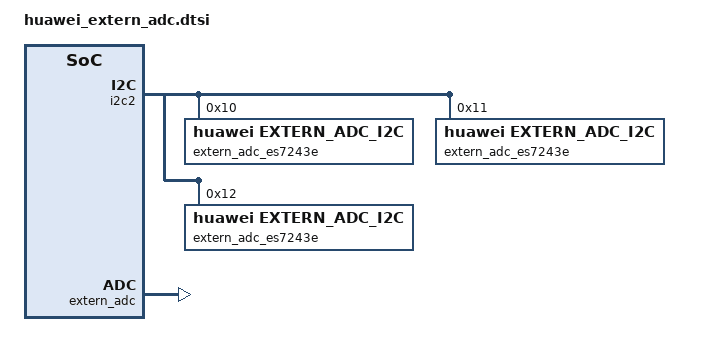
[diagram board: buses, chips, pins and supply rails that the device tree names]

&i2c2 {
	#address-cells = <1>;
	#size-cells = <0>;
	extern_adc_es7243e@10{
				compatible = "huawei,extern_adc_i2c";
				reg = <0x10>;
				chip_id = <2>;
				chip_model = "es7243e";
				status = "okay";

				/* reg_ctl node: a node contains five data <addr mask value delay ctl_type> */
				version_regs = <
					0xfd 0xff 0x7a 0 0
					0xfe 0xff 0x43 0 0
				>;

				init_regs = <
					0xf9 0xff 0x00 0 1
					0x02 0xff 0x80 0 1
					0x03 0xff 0x20 0 1
					0x0d 0xff 0xc0 0 1
					0x04 0xff 0x01 0 1
					0x05 0xff 0x00 0 1
					0x09 0xff 0xc5 0 1
					0x0a 0xff 0x81 0 1
					0x0b 0xff 0x00 0 1
					0x0c 0xff 0x13 0 1
					0x0e 0xff 0xbf 0 1
					0x0f 0xff 0x80 0 1
					0x14 0xff 0x04 0 1
					0x15 0xff 0x04 0 1
					0x16 0xff 0x00 0 1
					0x18 0xff 0x26 0 1
					0x17 0xff 0x02 0 1
					0x19 0xff 0x66 0 1
					0x1a 0xff 0x44 0 1
					0x1b 0xff 0x44 0 1
					0x1c 0xff 0x44 0 1
					0x1d 0xff 0x3c 0 1
					0x1e 0xff 0x0f 0 1
					0x1f 0xff 0x07 0 1
					0x20 0xff 0x10 0 1
					0x21 0xff 0x10 0 1
					0x00 0xff 0x80 0 1
					0x01 0xff 0x3a 0 1
					0x16 0xff 0x3f 0 1
					0x16 0xff 0x00 20 1
					0x16 0xff 0x03 20 1
					0x16 0xff 0x00 0 1
					0x14 0xff 0x0c 0 1
					0x15 0xff 0x0c 0 1
					0x20 0xff 0x1a 0 1
					0x21 0xff 0x1a 0 1
					0x0b 0xc0 0xc0 0 1
					0x04 0xff 0x02 0 1
					0x04 0xff 0x01 0 1
					0xf7 0xff 0x30 0 1
					0xf9 0xff 0x01 0 1
					0x16 0xff 0xff 0 1
					0x01 0xff 0x38 0 1
					0x20 0x10 0x00 0 1
					0x21 0x10 0x00 0 1
					0x00 0xff 0x00 0 1
					0x00 0xff 0x1e 0 1
					0x01 0xff 0x30 0 1
					0x01 0xff 0x00 0 1
				>;

				poweron_regs = <
					0x01 0xff 0x3a 0 1
					0x0b 0xc0 0xc0 0 1
					0x00 0xff 0x80 0 1
					0x14 0x1f 0x04 0 1
					0x15 0x1f 0x04 0 1
					0x16 0xff 0x00 0 1
					0x17 0xff 0x02 0 1
					0x14 0x1f 0x0c 40 1
					0x15 0x1f 0x0c 0 1
					0x20 0x10 0x10 0 1
					0x21 0x10 0x10 0 1
					0x0b 0xc0 0x00 40 1
				>;

				poweroff_regs = <
					0x0b 0xc0 0xc0 0 1
					0x04 0xff 0x02 20 1
					0x04 0xff 0x01 0 1
					0xf7 0xff 0x30 0 1
					0xf9 0xff 0x01 0 1
					0x16 0xff 0xff 0 1
					0x17 0xff 0x00 0 1
					0x01 0xff 0x38 0 1
					0x20 0x10 0x00 0 1
					0x21 0x10 0x00 0 1
					0x00 0xff 0x00 0 1
					0x00 0xff 0x1e 0 1
					0x01 0xff 0x30 0 1
					0x01 0xff 0x00 0 1
				>;

				/* pga_regs: a node contains five data <addr mask min_value delay max_value> */
				pga_volume_regs = <
					0x20 0x0f 0 0 14
					0x21 0x0f 0 0 14
				>;

				/* kctl_regs: always only has one elem, a node contains five data<addr mask min_value delay max_value> */
				tdm_mode_regs = <
					0x0c 0x0f 0 0 9
				>;

				data_sel_regs = <
					0x0d 0xc0 0 0 3
				>;

				mute_ctl_regs = <
					0x0b 0xc0 0 0 3
				>;

				/* dump reg ctl node: < addr reg_nums 0 0 ctl_type:5> */
				dump_regs = <0 256 0 0 5>;


				regmap_cfg {
					reg_bits = <8>;
					val_bits = <8>;
					/* 0 REGCACHE_NONE, 1 REGCACHE_RBTREE, 2 REGCACHE_COMPRESSED, 3 REGCACHE_FLAT */
					cache_type = <0>;
					max_register = <0xff>;
				};
			};

			extern_adc_es7243e@11{
				compatible = "huawei,extern_adc_i2c";
				reg = <0x11>;
				chip_id = <1>;
				chip_model = "es7243e";
				status = "okay";

				/* reg_ctl node: a node contains five data <addr mask value delay ctl_type> */
				version_regs = <
					0xfd 0xff 0x7a 0 0
					0xfe 0xff 0x43 0 0
				>;

				init_regs = <
					0xf9 0xff 0x00 0 1
					0x02 0xff 0x80 0 1
					0x03 0xff 0x20 0 1
					0x0d 0xff 0x00 0 1
					0x04 0xff 0x01 0 1
					0x05 0xff 0x00 0 1
					0x09 0xff 0xc5 0 1
					0x0a 0xff 0x81 0 1
					0x0b 0xff 0x00 0 1
					0x0c 0xff 0x23 0 1
					0x0e 0xff 0xbf 0 1
					0x0f 0xff 0x80 0 1
					0x14 0xff 0x04 0 1
					0x15 0xff 0x04 0 1
					0x16 0xff 0x00 0 1
					0x18 0xff 0x26 0 1
					0x17 0xff 0x02 0 1
					0x19 0xff 0x66 0 1
					0x1a 0xff 0x44 0 1
					0x1b 0xff 0x44 0 1
					0x1c 0xff 0x44 0 1
					0x1d 0xff 0x3c 0 1
					0x1e 0xff 0x0f 0 1
					0x1f 0xff 0x07 0 1
					0x20 0xff 0x10 0 1
					0x21 0xff 0x10 0 1
					0x00 0xff 0x80 0 1
					0x01 0xff 0x3a 0 1
					0x16 0xff 0x3f 0 1
					0x16 0xff 0x00 20 1
					0x16 0xff 0x03 20 1
					0x16 0xff 0x00 0 1
					0x14 0xff 0x0c 0 1
					0x15 0xff 0x0c 0 1
					0x20 0xff 0x1a 0 1
					0x21 0xff 0x1a 0 1
					0x0b 0xc0 0xc0 0 1
					0x04 0xff 0x02 0 1
					0x04 0xff 0x01 0 1
					0xf7 0xff 0x30 0 1
					0xf9 0xff 0x01 0 1
					0x16 0xff 0xff 0 1
					0x01 0xff 0x38 0 1
					0x20 0x10 0x00 0 1
					0x21 0x10 0x00 0 1
					0x00 0xff 0x00 0 1
					0x00 0xff 0x1e 0 1
					0x01 0xff 0x30 0 1
					0x01 0xff 0x00 0 1
				>;

				poweron_regs = <
					0x01 0xff 0x3a 0 1
					0x0b 0xc0 0xc0 0 1
					0x00 0xff 0x80 0 1
					0x14 0x1f 0x04 0 1
					0x15 0x1f 0x04 0 1
					0x16 0xff 0x00 0 1
					0x17 0xff 0x02 0 1
					0x14 0x1f 0x0c 40 1
					0x15 0x1f 0x0c 0 1
					0x20 0x10 0x10 0 1
					0x21 0x10 0x10 0 1
					0x0b 0xc0 0x00 40 1
				>;

				poweroff_regs = <
					0x0b 0xc0 0xc0 0 1
					0x04 0xff 0x02 20 1
					0x04 0xff 0x01 0 1
					0xf7 0xff 0x30 0 1
					0xf9 0xff 0x01 0 1
					0x16 0xff 0xff 0 1
					0x17 0xff 0x00 0 1
					0x01 0xff 0x38 0 1
					0x20 0x10 0x00 0 1
					0x21 0x10 0x00 0 1
					0x00 0xff 0x00 0 1
					0x00 0xff 0x1e 0 1
					0x01 0xff 0x30 0 1
					0x01 0xff 0x00 0 1
				>;


				/* pga_regs: a node contains five data<addr mask min_value delay max_value> */
				pga_volume_regs = <
					0x20 0x0f 0 0 14
					0x21 0x0f 0 0 14
				>;

				/* kctl_regs: always only has one elem, a node contains five data<addr mask min_value delay max_value> */
				tdm_mode_regs = <
					0x0c 0x0f 0 0 9
				>;

				data_sel_regs = <
					0x0d 0xc0 0 0 3
				>;

				mute_ctl_regs = <
					0x0b 0xc0 0 0 3
				>;

				/* dump reg ctl node: < addr reg_nums 0 0 ctl_type:5> */
				dump_regs = <0 256 0 0 5>;

				regmap_cfg {
					reg_bits = <8>;
					val_bits = <8>;
					/* 0 REGCACHE_NONE, 1 REGCACHE_RBTREE, 2 REGCACHE_COMPRESSED, 3 REGCACHE_FLAT */
					cache_type = <0>;
					max_register = <0xff>;
				};
			};

			extern_adc_es7243e@12{
				compatible = "huawei,extern_adc_i2c";
				reg = <0x12>;
				chip_id = <0>;
				chip_model = "es7243e";
				status = "okay";

				/* reg_ctl node: a node contains five data<addr mask value delay ctl_type> */
				version_regs = <
					0xfd 0xff 0x7a 0 0
					0xfe 0xff 0x43 0 0
				>;

				init_regs = <
					0xf9 0xff 0x00 0 1
					0x02 0xff 0x80 0 1
					0x03 0xff 0x20 0 1
					0x0d 0xff 0x00 0 1
					0x04 0xff 0x01 0 1
					0x05 0xff 0x00 0 1
					0x09 0xff 0xc5 0 1
					0x0a 0xff 0x81 0 1
					0x0b 0xff 0x00 0 1
					0x0c 0xff 0x23 0 1
					0x0e 0xff 0xbf 0 1
					0x0f 0xff 0x80 0 1
					0x14 0xff 0x04 0 1
					0x15 0xff 0x04 0 1
					0x16 0xff 0x00 0 1
					0x18 0xff 0x26 0 1
					0x17 0xff 0x02 0 1
					0x19 0xff 0x66 0 1
					0x1a 0xff 0x44 0 1
					0x1b 0xff 0x44 0 1
					0x1c 0xff 0x44 0 1
					0x1d 0xff 0x3c 0 1
					0x1e 0xff 0x0f 0 1
					0x1f 0xff 0x07 0 1
					0x20 0xff 0x10 0 1
					0x21 0xff 0x10 0 1
					0x00 0xff 0x80 0 1
					0x01 0xff 0x3a 0 1
					0x16 0xff 0x3f 0 1
					0x16 0xff 0x00 20 1
					0x16 0xff 0x03 20 1
					0x16 0xff 0x00 0 1
					0x14 0xff 0x0c 0 1
					0x15 0xff 0x0c 0 1
					0x20 0xff 0x1a 0 1
					0x21 0xff 0x1a 0 1
					0x0b 0xc0 0xc0 0 1
					0x04 0xff 0x02 0 1
					0x04 0xff 0x01 0 1
					0xf7 0xff 0x30 0 1
					0xf9 0xff 0x01 0 1
					0x16 0xff 0xff 0 1
					0x01 0xff 0x38 0 1
					0x20 0x10 0x00 0 1
					0x21 0x10 0x00 0 1
					0x00 0xff 0x00 0 1
					0x00 0xff 0x1e 0 1
					0x01 0xff 0x30 0 1
					0x01 0xff 0x00 0 1
				>;

				poweron_regs = <
					0x01 0xff 0x3a 0 1
					0x0b 0xc0 0xc0 0 1
					0x00 0xff 0x80 0 1
					0x14 0x1f 0x04 0 1
					0x15 0x1f 0x04 0 1
					0x16 0xff 0x00 0 1
					0x17 0xff 0x02 0 1
					0x14 0x1f 0x0c 40 1
					0x15 0x1f 0x0c 0 1
					0x20 0x10 0x10 0 1
					0x21 0x10 0x10 0 1
					0x0b 0xc0 0x00 40 1
				>;

				poweroff_regs = <
					0x0b 0xc0 0xc0 0 1
					0x04 0xff 0x02 20 1
					0x04 0xff 0x01 0 1
					0xf7 0xff 0x30 0 1
					0xf9 0xff 0x01 0 1
					0x16 0xff 0xff 0 1
					0x17 0xff 0x00 0 1
					0x01 0xff 0x38 0 1
					0x20 0x10 0x00 0 1
					0x21 0x10 0x00 0 1
					0x00 0xff 0x00 0 1
					0x00 0xff 0x1e 0 1
					0x01 0xff 0x30 0 1
					0x01 0xff 0x00 0 1
				>;

				/* pga_regs: a node contains five data <addr mask min_value delay max_value> */
				pga_volume_regs = <
					0x20 0x0f 0 0 14
					0x21 0x0f 0 0 14
				>;

				/* kctl_regs: always only has one elem, a node contains five data<addr mask min_value delay max_value> */
				tdm_mode_regs = <
					0x0c 0x0f 0 0 9
				>;

				data_sel_regs = <
					0x0d 0xc0 0 0 3
				>;

				mute_ctl_regs = <
					0x0b 0xc0 0 0 3
				>;

				/* dump reg ctl node: < addr reg_nums 0 0 ctl_type:5> */
				dump_regs = <0 256 0 0 5>;

				regmap_cfg {
					reg_bits = <8>;
					val_bits = <8>;
					/* 0 REGCACHE_NONE, 1 REGCACHE_RBTREE, 2 REGCACHE_COMPRESSED, 3 REGCACHE_FLAT */
					cache_type = <0>;
					max_register = <0xff>;
				};
			};
};

&extern_adc {
	compatible = " huawei,extern_adc";
	/* Now, up to only support 8 adc */
	adc_num = <3>;
	adc_vdd_en = <&pio 145 0>; /* GPIO_145 */
	status = "ok";
};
